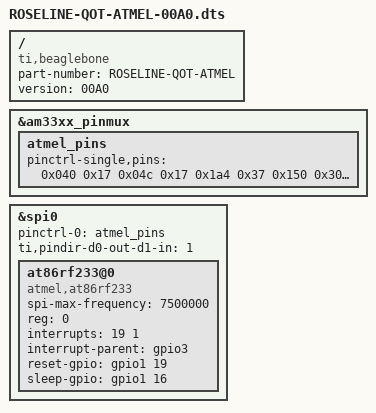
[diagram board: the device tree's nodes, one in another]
/dts-v1/;
/plugin/;
 
/ {
    /* what boards are we compatible with */
    compatible = "ti,beaglebone", "ti,beaglebone-black";
 
    /* identification */
    part-number = "ROSELINE-QOT-ATMEL";
 
    /* special version ignores EEPROM */
    version = "00A0";
 
    /* pin multiplexing */
    fragment@0 {
        target = <&am33xx_pinmux>;
        __overlay__ {
            atmel_pins: atmel_pins {
                pinctrl-single,pins = <
                    0x040 0x17      /* SLPTR P9.15 O_PULLUP | MODE7-GPIO1[16] */
                    0x04c 0x17      /* RSTN  P9.16 O_PULLUP | MODE7-GPIO1[19] */
                    0x1a4 0x37      /* IRQ   P9.27 I_PULLUP | MODE7-GPIO3[19] */
                    0x150 0x30      /* CLK   P9.22 spi0_sclk, I_PULLUP | MODE0 */
                    0x154 0x10      /* D0    P9.21 MOSI spi0_d0, O_PULLUP | MODE0 */
                    0x158 0x30      /* D1    P9.18 MISO spi0_d1, I_PULLUP | MODE0 */
                    0x15c 0x10      /* SS    P9.17 spi0_cs0, O_PULLUP | MODE0 */
                 >;
            };
        };
    };
 
    /* define the basic driverset for pinmuxing timers and initializing the qot kernel */
    fragment@1 {
        target = <&spi0>;
        __overlay__ {
            #address-cells = <1>;
            #size-cells = <0>;
            status = "okay";
            pinctrl-names = "default";
            pinctrl-0 = <&atmel_pins>;
            ti,pindir-d0-out-d1-in = <1>;
            at86rf233@0 {
                spi-max-frequency = <7500000>;
                reg = <0>;
                compatible = "atmel,at86rf233";
                interrupts = <19 1>;
                interrupt-parent = <&gpio3>;
                reset-gpio = <&gpio1 19 0>;
                sleep-gpio = <&gpio1 16 0>;
            };
        };
    };
};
